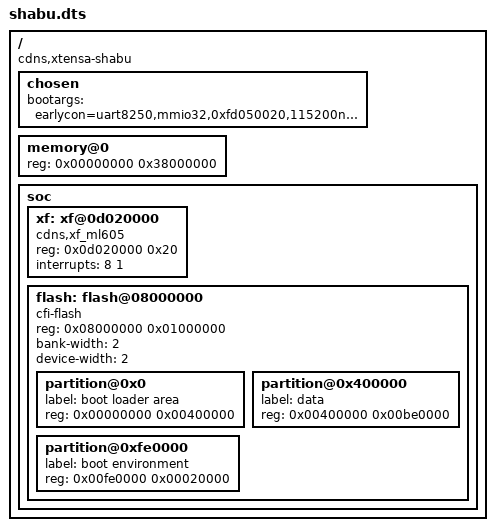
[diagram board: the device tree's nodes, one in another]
/dts-v1/;
/include/ "xtfpga.dtsi"

/ {
	compatible = "cdns,xtensa-shabu";
	chosen {
		bootargs = "earlycon=uart8250,mmio32,0xfd050020,115200n8 console=ttyS0,115200n8 ip=dhcp root=/dev/nfs rw debug memmap=0x38000000,0x02000000$0x06000000,0x1000$0x1000";
	};

	memory@0 {
		device_type = "memory";
		reg = <0x00000000 0x38000000>;
	};

	soc {
		xf: xf@0d020000 {
			compatible = "cdns,xf_ml605";
			reg = <0x0d020000 0x20>;
			interrupts = <8 1>;
		};
		flash: flash@08000000 {
			#address-cells = <1>;
			#size-cells = <1>;
			compatible = "cfi-flash";
			reg = <0x08000000 0x01000000>;
			bank-width = <2>;
			device-width = <2>;
			partition@0x0 {
				label = "boot loader area";
				reg = <0x00000000 0x00400000>;
			};
			partition@0x400000 {
				label = "data";
				reg = <0x00400000 0x00be0000>;
			};
			partition@0xfe0000 {
				label = "boot environment";
				reg = <0x00fe0000 0x00020000>;
			};
		};
	};
};
